AUTOSAR XML (schema 4-2-2)
package /ASW_COM_Package
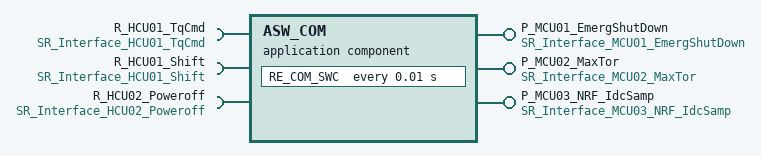
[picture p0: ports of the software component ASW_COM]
  application sw component type ASW_COM
    provide port P_MCU01_EmergShutDown: provided-interface=SR_Interface_MCU01_EmergShutDown
    provide port P_MCU02_MaxTor: provided-interface=SR_Interface_MCU02_MaxTor
    provide port P_MCU03_NRF_IdcSamp: provided-interface=SR_Interface_MCU03_NRF_IdcSamp
    require port R_HCU01_TqCmd: nonqueued-receiver-com-spec=data-element=DE_TqCmd, required-interface=SR_Interface_HCU01_TqCmd
    require port R_HCU01_Shift: nonqueued-receiver-com-spec=data-element=DE_Shift, required-interface=SR_Interface_HCU01_Shift
    require port R_HCU02_Poweroff: nonqueued-receiver-com-spec{data-element=DE_Poweroff, alive-timeout=0.3}, required-interface=SR_Interface_HCU02_Poweroff
    behavior IB_ASW_COM
      timing event TE_RE_COM_SWC_10ms: start-on-event=RE_COM_SWC, period=0.01
      runnable RE_COM_SWC
        data-access-points:
          6 x access:
            VA_Read_HCU01_TqCmd: access-direction=READ, accessed-variable=R_HCU01_TqCmd.DE_TqCmd
            VA_Read_HCU01_Shift: access-direction=READ, accessed-variable=R_HCU01_Shift.DE_Shift
            VA_Read_HCU02_Poweroff: access-direction=READ, accessed-variable=R_HCU02_Poweroff.DE_Poweroff
            VA_Write_MCU01_EmergShutDown: access-direction=WRITE, accessed-variable=P_MCU01_EmergShutDown.DE_EmergShutDown
            VA_Write_MCU02_MaxTor: access-direction=WRITE, accessed-variable=P_MCU02_MaxTor.DE_MaxTor
            VA_Write_MCU03_NRF_IdcSamp: access-direction=WRITE, accessed-variable=P_MCU03_NRF_IdcSamp.DE_IdcSamp
